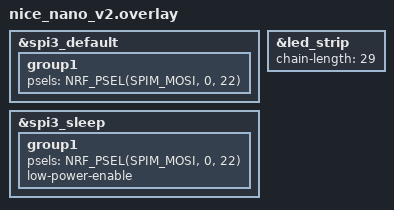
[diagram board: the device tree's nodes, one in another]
/*
 * RGB data is D4 / P0.22 on the Sofle Choc V3.5 PCB from 42.Keebs.
 * There are 58 in-switch LEDs total, i.e. 29 in each independently driven
 * half. No bottom-facing underglow LEDs exist on this PCB revision.
 *
 * SPDX-License-Identifier: MIT
 */

&spi3_default {
    group1 {
        psels = <NRF_PSEL(SPIM_MOSI, 0, 22)>;
    };
};

&spi3_sleep {
    group1 {
        psels = <NRF_PSEL(SPIM_MOSI, 0, 22)>;
        low-power-enable;
    };
};

&led_strip {
    chain-length = <29>;
};
